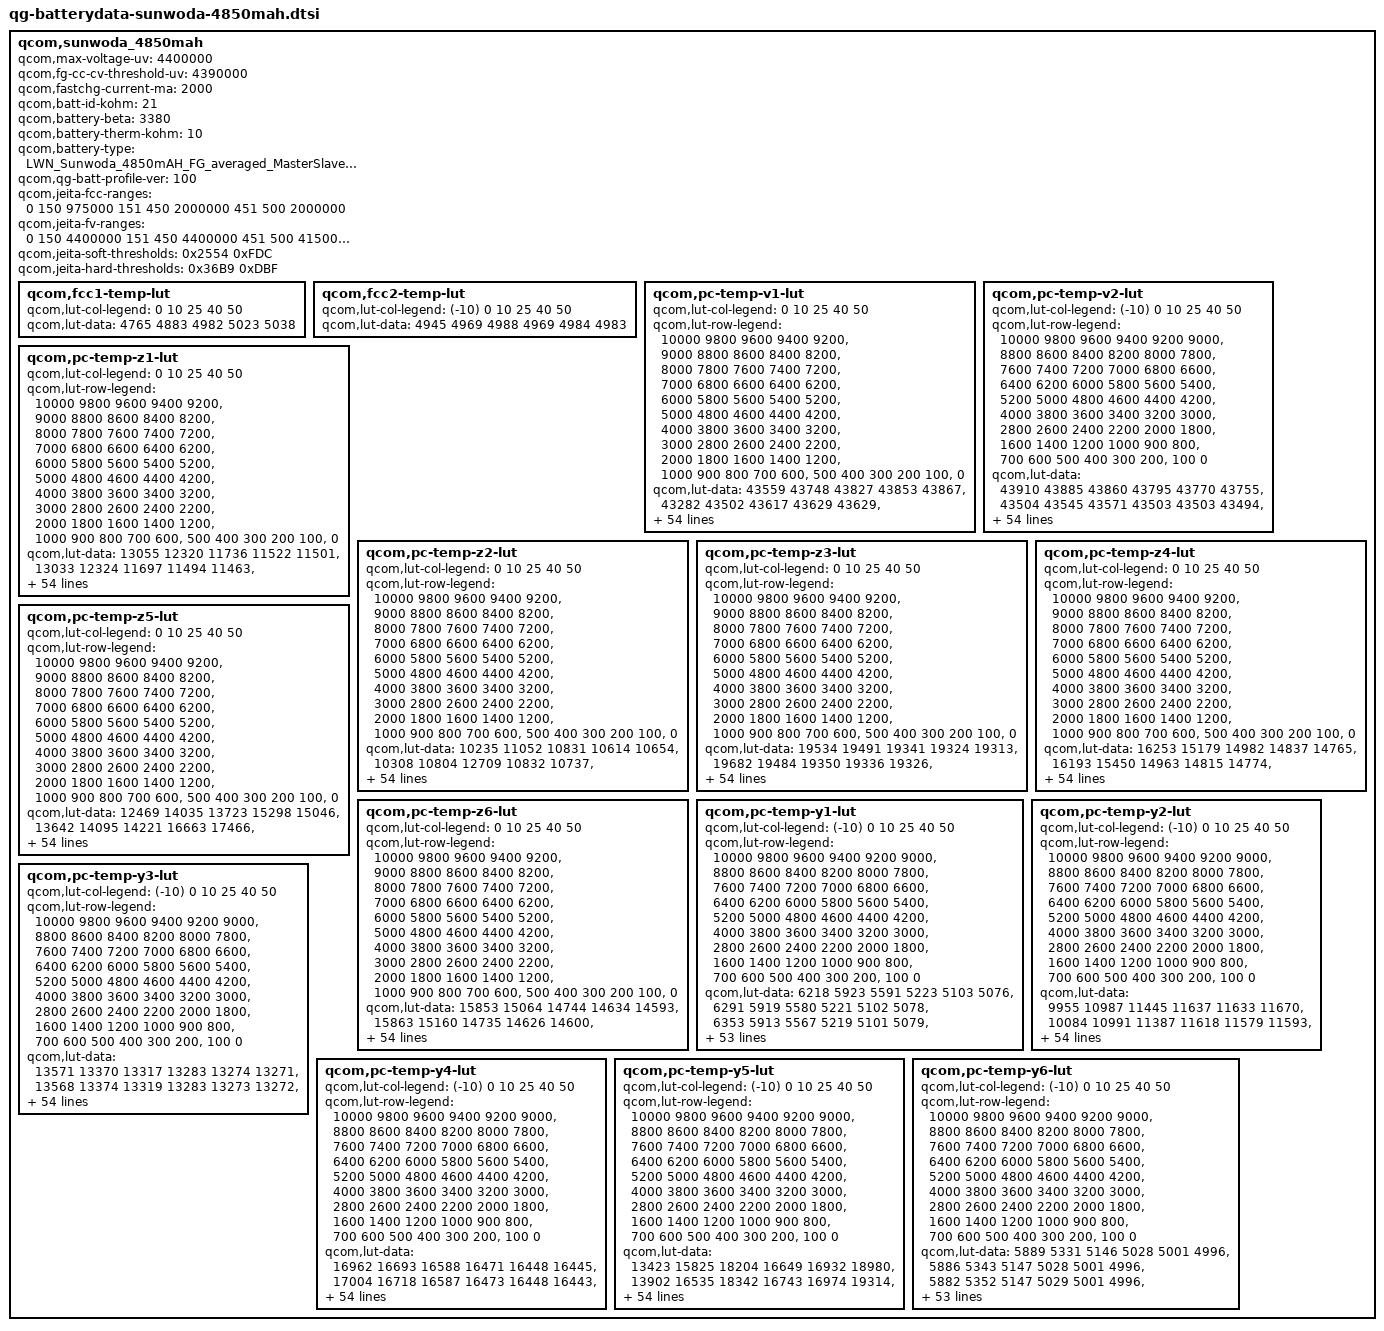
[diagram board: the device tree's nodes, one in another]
/* Copyright (c) 2018, The Linux Foundation. All rights reserved.
 *
 * This program is free software; you can redistribute it and/or modify
 * it under the terms of the GNU General Public License version 2 and
 * only version 2 as published by the Free Software Foundation.
 *
 * This program is distributed in the hope that it will be useful,
 * but WITHOUT ANY WARRANTY; without even the implied warranty of
 * MERCHANTABILITY or FITNESS FOR A PARTICULAR PURPOSE.  See the
 * GNU General Public License for more details.
 */

qcom,sunwoda_4850mah {
    /* 3757018_LC_P400_Sunwoda_4850mAH_FG_averaged_MasterSlave_Jan3th2019 */
    qcom,max-voltage-uv = <4400000>;
    qcom,fg-cc-cv-threshold-uv = <4390000>;
    qcom,fastchg-current-ma = <2000>;
    qcom,batt-id-kohm = <21>;
    qcom,battery-beta = <3380>;
    qcom,battery-therm-kohm = <10>;
    qcom,battery-type = "LWN_Sunwoda_4850mAH_FG_averaged_MasterSlave_Jan3th2019";
    qcom,qg-batt-profile-ver = <100>;

	qcom,jeita-fcc-ranges = <0   150   975000
				151  450  2000000
				451  500  2000000>;
	qcom,jeita-fv-ranges =  <0   150  4400000
				151  450  4400000
				451  500  4150000>;

	/* COOL = 15 DegC, WARM = 45 DegC */
	qcom,jeita-soft-thresholds = <0x2554 0xFDC>;
	/* COLD = 0 DegC, HOT = 50 DegC */
	qcom,jeita-hard-thresholds = <0x36B9 0xDBF>;

	qcom,fcc1-temp-lut {
		qcom,lut-col-legend = <0 10 25 40 50>;
		qcom,lut-data = <4765 4883 4982 5023 5038>;
	};

	qcom,fcc2-temp-lut {
		qcom,lut-col-legend = <(-10) 0 10 25 40 50>;
		qcom,lut-data = <4945 4969 4988 4969 4984 4983>;
	};

	qcom,pc-temp-v1-lut {
		qcom,lut-col-legend = <0 10 25 40 50>;
		qcom,lut-row-legend = <10000 9800 9600 9400 9200>,
			<9000 8800 8600 8400 8200>,
			<8000 7800 7600 7400 7200>,
			<7000 6800 6600 6400 6200>,
			<6000 5800 5600 5400 5200>,
			<5000 4800 4600 4400 4200>,
			<4000 3800 3600 3400 3200>,
			<3000 2800 2600 2400 2200>,
			<2000 1800 1600 1400 1200>,
			<1000 900 800 700 600>,
			<500 400 300 200 100>,
			<0>;
		qcom,lut-data = <43559 43748 43827 43853 43867>,
			<43282 43502 43617 43629 43629>,
			<43027 43242 43397 43402 43411>,
			<42793 42990 43144 43171 43183>,
			<42570 42751 42892 42939 42951>,
			<42350 42518 42646 42702 42717>,
			<42137 42289 42404 42463 42482>,
			<41926 42065 42169 42226 42249>,
			<41715 41847 41941 41993 42018>,
			<41512 41631 41718 41763 41790>,
			<41334 41425 41494 41537 41562>,
			<41176 41251 41286 41317 41338>,
			<40983 41098 41112 41106 41119>,
			<40685 40902 40947 40905 40905>,
			<40362 40587 40723 40697 40697>,
			<40122 40267 40407 40468 40495>,
			<39926 40060 40148 40249 40300>,
			<39772 39900 39997 40074 40116>,
			<39665 39763 39874 39921 39941>,
			<39573 39652 39735 39767 39772>,
			<39464 39539 39591 39614 39616>,
			<39339 39391 39414 39442 39449>,
			<39210 39215 39142 39192 39219>,
			<39079 39026 38879 38921 38961>,
			<38947 38803 38729 38760 38789>,
			<38813 38614 38622 38658 38675>,
			<38671 38511 38529 38564 38573>,
			<38547 38439 38449 38466 38466>,
			<38456 38377 38376 38374 38367>,
			<38382 38322 38305 38288 38277>,
			<38330 38275 38240 38209 38196>,
			<38292 38234 38181 38139 38124>,
			<38261 38197 38127 38079 38062>,
			<38235 38165 38078 38024 38004>,
			<38214 38137 38039 37972 37947>,
			<38189 38109 38004 37923 37892>,
			<38166 38080 37967 37875 37832>,
			<38136 38047 37930 37828 37771>,
			<38087 37999 37881 37771 37701>,
			<38010 37914 37800 37689 37618>,
			<37916 37811 37697 37588 37520>,
			<37794 37698 37585 37478 37410>,
			<37652 37566 37456 37352 37280>,
			<37487 37407 37302 37200 37128>,
			<37343 37262 37157 37058 36989>,
			<37242 37162 37064 36969 36907>,
			<37218 37137 37040 36945 36884>,
			<37187 37114 37023 36930 36868>,
			<37160 37093 37007 36913 36851>,
			<37121 37057 36970 36867 36799>,
			<36933 36861 36758 36634 36546>,
			<36506 36443 36340 36209 36116>,
			<35946 35880 35777 35644 35551>,
			<35189 35121 35012 34877 34785>,
			<34007 33947 33837 33700 33602>,
			<30000 30000 30000 30000 30000>;
	};

	qcom,pc-temp-v2-lut {
		qcom,lut-col-legend = <(-10) 0 10 25 40 50>;
		qcom,lut-row-legend = <10000 9800 9600 9400 9200 9000>,
			<8800 8600 8400 8200 8000 7800>,
			<7600 7400 7200 7000 6800 6600>,
			<6400 6200 6000 5800 5600 5400>,
			<5200 5000 4800 4600 4400 4200>,
			<4000 3800 3600 3400 3200 3000>,
			<2800 2600 2400 2200 2000 1800>,
			<1600 1400 1200 1000 900 800>,
			<700 600 500 400 300 200>,
			<100 0>;
		qcom,lut-data = <43910 43885 43860 43795 43770 43755>,
			<43504 43545 43571 43503 43503 43494>,
			<43144 43234 43297 43228 43244 43239>,
			<42835 42957 43037 42971 42996 42994>,
			<42567 42710 42790 42731 42758 42758>,
			<42328 42468 42548 42495 42522 42523>,
			<42125 42222 42309 42260 42288 42288>,
			<41926 41984 42074 42028 42056 42055>,
			<41634 41764 41848 41802 41827 41825>,
			<41255 41556 41628 41581 41601 41598>,
			<41115 41354 41409 41361 41377 41374>,
			<41137 41162 41186 41138 41154 41156>,
			<41161 40970 40976 40923 40938 40941>,
			<40928 40779 40805 40737 40742 40734>,
			<40254 40581 40648 40564 40555 40530>,
			<39807 40313 40426 40355 40356 40333>,
			<39585 39887 40091 40076 40140 40140>,
			<39407 39538 39793 39837 39939 39957>,
			<39240 39395 39609 39707 39776 39790>,
			<39091 39294 39455 39602 39624 39626>,
			<38931 39157 39279 39438 39436 39436>,
			<38761 38980 39085 39183 39209 39216>,
			<38593 38809 38909 38947 38998 39008>,
			<38416 38660 38757 38772 38810 38818>,
			<38250 38521 38619 38621 38643 38647>,
			<38157 38393 38497 38496 38512 38512>,
			<38101 38273 38388 38390 38404 38402>,
			<38054 38164 38287 38293 38305 38301>,
			<38012 38057 38195 38203 38213 38210>,
			<37974 37968 38108 38120 38128 38126>,
			<37934 37918 38023 38046 38053 38048>,
			<37893 37883 37942 37977 37984 37976>,
			<37852 37852 37877 37914 37920 37912>,
			<37809 37823 37824 37854 37862 37857>,
			<37765 37795 37780 37798 37801 37795>,
			<37717 37763 37745 37743 37721 37701>,
			<37665 37728 37713 37690 37631 37589>,
			<37607 37688 37673 37630 37546 37490>,
			<37541 37641 37625 37561 37464 37399>,
			<37470 37580 37565 37487 37383 37314>,
			<37398 37486 37483 37412 37311 37241>,
			<37320 37371 37384 37325 37227 37160>,
			<37238 37255 37269 37209 37113 37045>,
			<37151 37132 37136 37078 36986 36918>,
			<37062 37011 36994 36929 36845 36785>,
			<36966 36916 36922 36880 36807 36749>,
			<36920 36881 36903 36867 36795 36738>,
			<36875 36850 36885 36851 36782 36727>,
			<36827 36801 36859 36829 36757 36701>,
			<36752 36727 36802 36773 36691 36620>,
			<36603 36552 36611 36584 36445 36347>,
			<36274 36179 36180 36142 35984 35875>,
			<35755 35599 35574 35546 35373 35258>,
			<34996 34802 34747 34753 34546 34410>,
			<33825 33539 33456 33568 33298 33144>,
			<31360 29501 29420 29354 29436 29519>;
	};

	qcom,pc-temp-z1-lut {
		qcom,lut-col-legend = <0 10 25 40 50>;
		qcom,lut-row-legend = <10000 9800 9600 9400 9200>,
			<9000 8800 8600 8400 8200>,
			<8000 7800 7600 7400 7200>,
			<7000 6800 6600 6400 6200>,
			<6000 5800 5600 5400 5200>,
			<5000 4800 4600 4400 4200>,
			<4000 3800 3600 3400 3200>,
			<3000 2800 2600 2400 2200>,
			<2000 1800 1600 1400 1200>,
			<1000 900 800 700 600>,
			<500 400 300 200 100>,
			<0>;
		qcom,lut-data = <13055 12320 11736 11522 11501>,
			<13033 12324 11697 11494 11463>,
			<13010 12288 11679 11483 11455>,
			<12993 12262 11665 11476 11450>,
			<12988 12250 11655 11471 11447>,
			<12991 12241 11649 11468 11446>,
			<12995 12227 11644 11465 11445>,
			<12993 12208 11639 11465 11445>,
			<12954 12196 11634 11465 11447>,
			<12911 12191 11633 11466 11448>,
			<12908 12188 11635 11466 11448>,
			<12918 12183 11636 11465 11448>,
			<12922 12179 11637 11466 11448>,
			<12905 12172 11637 11467 11448>,
			<12873 12151 11635 11468 11448>,
			<12839 12133 11623 11465 11449>,
			<12796 12132 11616 11462 11449>,
			<12776 12135 11621 11463 11450>,
			<12777 12138 11628 11466 11451>,
			<12780 12143 11634 11468 11452>,
			<12783 12150 11639 11469 11453>,
			<12794 12162 11644 11470 11454>,
			<12806 12180 11647 11471 11455>,
			<12818 12188 11650 11473 11456>,
			<12832 12192 11654 11475 11457>,
			<12837 12195 11658 11478 11460>,
			<12837 12197 11662 11481 11463>,
			<12839 12199 11666 11483 11465>,
			<12856 12202 11670 11485 11467>,
			<12884 12207 11675 11488 11469>,
			<12892 12212 11680 11492 11471>,
			<12882 12217 11684 11495 11472>,
			<12872 12221 11688 11497 11475>,
			<12872 12224 11692 11498 11477>,
			<12874 12226 11697 11501 11479>,
			<12878 12229 11703 11503 11480>,
			<12889 12233 11708 11505 11482>,
			<12903 12240 11712 11508 11483>,
			<12913 12246 11717 11510 11484>,
			<12923 12252 11720 11512 11485>,
			<12929 12260 11724 11513 11487>,
			<12942 12276 11729 11516 11488>,
			<12950 12292 11734 11518 11490>,
			<12944 12296 11740 11521 11492>,
			<12946 12294 11748 11524 11493>,
			<12949 12305 11754 11526 11494>,
			<12921 12300 11753 11525 11494>,
			<12937 12292 11758 11526 11493>,
			<12919 12290 11757 11526 11494>,
			<12941 12319 11759 11528 11496>,
			<12939 12331 11769 11532 11498>,
			<12934 12340 11778 11537 11503>,
			<12946 12335 11789 11546 11510>,
			<13009 12379 11811 11558 11519>,
			<13009 12379 11811 11558 11519>,
			<13009 12379 11811 11558 11519>;
	};

	qcom,pc-temp-z2-lut {
		qcom,lut-col-legend = <0 10 25 40 50>;
		qcom,lut-row-legend = <10000 9800 9600 9400 9200>,
			<9000 8800 8600 8400 8200>,
			<8000 7800 7600 7400 7200>,
			<7000 6800 6600 6400 6200>,
			<6000 5800 5600 5400 5200>,
			<5000 4800 4600 4400 4200>,
			<4000 3800 3600 3400 3200>,
			<3000 2800 2600 2400 2200>,
			<2000 1800 1600 1400 1200>,
			<1000 900 800 700 600>,
			<500 400 300 200 100>,
			<0>;
		qcom,lut-data = <10235 11052 10831 10614 10654>,
			<10308 10804 12709 10832 10737>,
			<10347 10628 13825 11026 10757>,
			<10370 10537 12805 11506 10788>,
			<10389 10496 11906 11836 10820>,
			<10409 10464 11172 11546 10816>,
			<10429 10443 10705 10950 10774>,
			<10434 10426 10750 10790 10748>,
			<10423 10420 10930 10769 10667>,
			<10405 10418 11025 10761 10602>,
			<10391 10417 11236 11003 10576>,
			<10376 10420 11403 11351 10524>,
			<10358 10429 11373 11425 10521>,
			<10333 10435 11312 11443 10545>,
			<10305 10434 11332 11471 10571>,
			<10286 10434 11516 11546 10596>,
			<10269 10437 11627 11607 10621>,
			<10263 10445 11266 11377 10644>,
			<10274 10460 10774 10835 10665>,
			<10296 10506 10737 10684 10692>,
			<10315 10565 10838 10726 10734>,
			<10332 10617 10901 10768 10764>,
			<10350 10667 10908 10792 10762>,
			<10371 10702 10905 10815 10756>,
			<10394 10728 10896 10818 10772>,
			<10423 10742 10874 10812 10880>,
			<10463 10738 10863 10832 10971>,
			<10491 10725 10881 10913 11008>,
			<10500 10718 10903 10998 11013>,
			<10505 10714 10933 11000 10925>,
			<10505 10712 10979 10952 10722>,
			<10500 10718 10995 10931 10616>,
			<10495 10732 10998 10887 10609>,
			<10491 10746 10998 10850 10630>,
			<10490 10759 10988 10879 10676>,
			<10492 10771 10974 10948 10754>,
			<10504 10780 10982 11023 10841>,
			<10520 10789 11015 11114 10949>,
			<10539 10804 11051 11191 11030>,
			<10564 10833 11090 11253 11072>,
			<10585 10852 11125 11296 11103>,
			<10599 10850 11142 11279 11120>,
			<10619 10847 11152 11204 11114>,
			<10665 10859 11154 11137 11076>,
			<10936 10976 11180 11106 11041>,
			<11079 11096 11217 11118 11031>,
			<10952 11113 11165 11115 11018>,
			<10938 11143 11128 11093 10996>,
			<10920 11174 11179 11120 11062>,
			<10854 11221 11170 11271 11332>,
			<10961 11264 11432 11191 10927>,
			<10790 11386 11359 10961 10717>,
			<10568 11294 11363 10862 10591>,
			<10341 11158 11347 10768 10593>,
			<10341 11158 11347 10768 10593>,
			<10341 11158 11347 10768 10593>;
	};

	qcom,pc-temp-z3-lut {
		qcom,lut-col-legend = <0 10 25 40 50>;
		qcom,lut-row-legend = <10000 9800 9600 9400 9200>,
			<9000 8800 8600 8400 8200>,
			<8000 7800 7600 7400 7200>,
			<7000 6800 6600 6400 6200>,
			<6000 5800 5600 5400 5200>,
			<5000 4800 4600 4400 4200>,
			<4000 3800 3600 3400 3200>,
			<3000 2800 2600 2400 2200>,
			<2000 1800 1600 1400 1200>,
			<1000 900 800 700 600>,
			<500 400 300 200 100>,
			<0>;
		qcom,lut-data = <19534 19491 19341 19324 19313>,
			<19682 19484 19350 19336 19326>,
			<19726 19549 19364 19370 19347>,
			<19728 19578 19422 19383 19357>,
			<19728 19579 19448 19389 19363>,
			<19716 19580 19446 19389 19366>,
			<19685 19580 19444 19386 19368>,
			<19666 19579 19449 19386 19368>,
			<19659 19578 19458 19385 19364>,
			<19654 19571 19461 19385 19359>,
			<19650 19559 19465 19384 19355>,
			<19646 19545 19468 19383 19350>,
			<19645 19528 19460 19382 19347>,
			<19671 19523 19448 19380 19343>,
			<19704 19531 19446 19378 19341>,
			<19706 19539 19449 19376 19337>,
			<19690 19534 19450 19373 19334>,
			<19670 19515 19420 19362 19331>,
			<19641 19502 19379 19343 19329>,
			<19612 19492 19374 19335 19327>,
			<19604 19487 19375 19332 19324>,
			<19606 19487 19377 19331 19321>,
			<19610 19490 19393 19334 19318>,
			<19615 19495 19409 19339 19316>,
			<19620 19504 19406 19338 19314>,
			<19627 19511 19395 19325 19311>,
			<19642 19509 19386 19318 19310>,
			<19652 19504 19379 19327 19330>,
			<19651 19500 19375 19340 19356>,
			<19649 19496 19377 19348 19358>,
			<19645 19492 19383 19360 19354>,
			<19639 19490 19389 19364 19350>,
			<19631 19488 19396 19359 19342>,
			<19625 19486 19400 19353 19334>,
			<19618 19485 19398 19349 19329>,
			<19611 19483 19394 19345 19325>,
			<19602 19480 19390 19342 19324>,
			<19592 19476 19387 19338 19325>,
			<19584 19472 19383 19335 19325>,
			<19577 19468 19379 19334 19324>,
			<19569 19464 19376 19333 19323>,
			<19559 19461 19375 19332 19324>,
			<19548 19457 19375 19331 19327>,
			<19536 19451 19372 19330 19327>,
			<19478 19429 19365 19326 19325>,
			<19434 19409 19354 19320 19314>,
			<19326 19399 19350 19317 19311>,
			<19319 19390 19343 19314 19308>,
			<19307 19386 19340 19313 19302>,
			<19295 19386 19331 19306 19294>,
			<19308 19381 19319 19313 19320>,
			<19319 19346 19320 19321 19324>,
			<19322 19353 19317 19320 19324>,
			<19317 19329 19310 19320 19312>,
			<19317 19329 19310 19320 19312>,
			<19317 19329 19310 19320 19312>;
	};

	qcom,pc-temp-z4-lut {
		qcom,lut-col-legend = <0 10 25 40 50>;
		qcom,lut-row-legend = <10000 9800 9600 9400 9200>,
			<9000 8800 8600 8400 8200>,
			<8000 7800 7600 7400 7200>,
			<7000 6800 6600 6400 6200>,
			<6000 5800 5600 5400 5200>,
			<5000 4800 4600 4400 4200>,
			<4000 3800 3600 3400 3200>,
			<3000 2800 2600 2400 2200>,
			<2000 1800 1600 1400 1200>,
			<1000 900 800 700 600>,
			<500 400 300 200 100>,
			<0>;
		qcom,lut-data = <16253 15179 14982 14837 14765>,
			<16193 15450 14963 14815 14774>,
			<16088 15343 14997 14864 14817>,
			<15885 15234 14916 14828 14803>,
			<15676 15139 14860 14788 14779>,
			<15548 15052 14838 14771 14760>,
			<15448 14985 14819 14758 14743>,
			<15365 14931 14788 14744 14728>,
			<15297 14892 14748 14726 14714>,
			<15236 14867 14719 14708 14702>,
			<15170 14846 14691 14692 14697>,
			<15102 14819 14669 14677 14693>,
			<15053 14790 14657 14668 14688>,
			<15026 14779 14649 14660 14682>,
			<15003 14779 14648 14656 14676>,
			<14973 14779 14654 14655 14671>,
			<14936 14772 14662 14655 14666>,
			<14901 14752 14674 14656 14660>,
			<14873 14733 14685 14659 14653>,
			<14848 14713 14685 14659 14650>,
			<14830 14699 14680 14659 14650>,
			<14812 14703 14679 14659 14651>,
			<14802 14718 14732 14704 14690>,
			<14799 14740 14790 14780 14768>,
			<14798 14788 14798 14794 14785>,
			<14799 14825 14800 14792 14778>,
			<14809 14823 14800 14790 14768>,
			<14819 14815 14793 14770 14736>,
			<14823 14806 14781 14740 14695>,
			<14827 14797 14766 14717 14680>,
			<14828 14786 14748 14693 14672>,
			<14821 14776 14732 14679 14667>,
			<14812 14766 14716 14672 14662>,
			<14803 14756 14705 14668 14659>,
			<14793 14746 14700 14668 14660>,
			<14782 14737 14697 14669 14661>,
			<14771 14729 14696 14671 14663>,
			<14761 14722 14695 14674 14668>,
			<14750 14720 14695 14678 14673>,
			<14740 14720 14701 14686 14678>,
			<14733 14720 14708 14693 14683>,
			<14730 14714 14705 14691 14680>,
			<14725 14702 14694 14685 14672>,
			<14713 14695 14690 14686 14674>,
			<14699 14678 14680 14685 14675>,
			<14707 14661 14659 14664 14660>,
			<14821 14662 14653 14658 14655>,
			<14825 14661 14648 14646 14642>,
			<14831 14658 14639 14628 14629>,
			<14835 14651 14643 14631 14631>,
			<14819 14664 14674 14650 14633>,
			<14828 14713 14681 14648 14635>,
			<14835 14712 14686 14649 14636>,
			<14853 14746 14696 14650 14647>,
			<14853 14746 14696 14650 14647>,
			<14853 14746 14696 14650 14647>;
	};

	qcom,pc-temp-z5-lut {
		qcom,lut-col-legend = <0 10 25 40 50>;
		qcom,lut-row-legend = <10000 9800 9600 9400 9200>,
			<9000 8800 8600 8400 8200>,
			<8000 7800 7600 7400 7200>,
			<7000 6800 6600 6400 6200>,
			<6000 5800 5600 5400 5200>,
			<5000 4800 4600 4400 4200>,
			<4000 3800 3600 3400 3200>,
			<3000 2800 2600 2400 2200>,
			<2000 1800 1600 1400 1200>,
			<1000 900 800 700 600>,
			<500 400 300 200 100>,
			<0>;
		qcom,lut-data = <12469 14035 13723 15298 15046>,
			<13642 14095 14221 16663 17466>,
			<14305 15310 14148 18876 18921>,
			<14672 16224 16323 19775 19970>,
			<14920 16679 17824 20300 20922>,
			<15069 17072 18500 20653 21636>,
			<15176 17710 19092 20971 22319>,
			<15319 18576 20359 21446 22605>,
			<15574 19117 22701 22366 22672>,
			<15898 19386 25071 23412 22729>,
			<16197 19556 28943 25500 22668>,
			<16499 19620 32210 28306 22437>,
			<17011 19699 33609 30520 22407>,
			<18890 19942 34526 32847 22821>,
			<20877 21937 34644 33999 23114>,
			<21144 23939 34341 34303 23274>,
			<21040 23953 33753 34023 23632>,
			<20924 23612 28463 31073 24484>,
			<20812 23648 21720 25630 26114>,
			<20707 26738 21273 24164 27053>,
			<21016 31251 23431 24733 27555>,
			<23097 34895 27080 25429 27842>,
			<25786 38531 39736 27253 26755>,
			<28359 42484 51620 29884 24083>,
			<31418 47804 48029 28926 21521>,
			<35614 51380 35896 21903 17985>,
			<42899 49221 28515 17730 16140>,
			<48146 43367 24502 17839 18570>,
			<48673 39546 22487 18708 22498>,
			<47979 37102 22699 20617 24742>,
			<46797 35799 23455 24327 26440>,
			<44614 35875 24886 27151 27187>,
			<42340 36219 29082 28917 27269>,
			<40820 36758 32941 30592 27358>,
			<39559 37974 35318 33008 28319>,
			<38523 39284 36967 35395 30180>,
			<37497 40320 37188 35668 31447>,
			<36835 41234 36986 34363 32419>,
			<37223 41644 36562 32568 32850>,
			<38515 41861 34189 29751 29712>,
			<39046 41892 31740 26807 25242>,
			<37145 41026 31719 25695 25094>,
			<35868 39551 32058 25095 26328>,
			<36417 38635 31164 23775 25718>,
			<31640 36815 30994 23139 24186>,
			<24416 34431 31333 23781 22267>,
			<13476 28486 28947 23008 21353>,
			<13195 25281 26834 23277 22231>,
			<12831 24214 26067 27506 23734>,
			<12521 25299 23048 24590 20660>,
			<13074 23780 17854 19778 24456>,
			<13189 16532 16608 19688 22939>,
			<13016 16266 15599 18353 21661>,
			<12656 14072 14417 17650 16644>,
			<12656 14072 14417 17650 16644>,
			<12656 14072 14417 17650 16644>;
	};

	qcom,pc-temp-z6-lut {
		qcom,lut-col-legend = <0 10 25 40 50>;
		qcom,lut-row-legend = <10000 9800 9600 9400 9200>,
			<9000 8800 8600 8400 8200>,
			<8000 7800 7600 7400 7200>,
			<7000 6800 6600 6400 6200>,
			<6000 5800 5600 5400 5200>,
			<5000 4800 4600 4400 4200>,
			<4000 3800 3600 3400 3200>,
			<3000 2800 2600 2400 2200>,
			<2000 1800 1600 1400 1200>,
			<1000 900 800 700 600>,
			<500 400 300 200 100>,
			<0>;
		qcom,lut-data = <15853 15064 14744 14634 14593>,
			<15863 15160 14735 14626 14600>,
			<15851 15137 14754 14662 14627>,
			<15756 15106 14747 14653 14624>,
			<15638 15063 14738 14641 14619>,
			<15561 15017 14726 14634 14614>,
			<15497 14983 14713 14626 14608>,
			<15446 14957 14701 14619 14601>,
			<15406 14935 14688 14611 14593>,
			<15372 14917 14678 14604 14586>,
			<15336 14902 14669 14596 14581>,
			<15299 14881 14661 14590 14576>,
			<15275 14858 14651 14585 14572>,
			<15266 14848 14641 14581 14567>,
			<15258 14847 14640 14577 14563>,
			<15240 14846 14643 14575 14559>,
			<15207 14840 14644 14573 14555>,
			<15175 14823 14632 14567 14551>,
			<15147 14808 14616 14558 14546>,
			<15125 14796 14613 14554 14544>,
			<15121 14789 14613 14552 14542>,
			<15120 14792 14614 14551 14541>,
			<15119 14803 14646 14573 14557>,
			<15121 14817 14680 14608 14588>,
			<15127 14843 14681 14614 14595>,
			<15134 14863 14678 14608 14592>,
			<15150 14862 14674 14602 14588>,
			<15162 14858 14668 14598 14585>,
			<15165 14853 14662 14594 14581>,
			<15167 14848 14657 14590 14577>,
			<15166 14843 14654 14586 14573>,
			<15163 14838 14651 14582 14568>,
			<15158 14834 14648 14577 14562>,
			<15153 14830 14646 14573 14557>,
			<15149 14826 14643 14570 14554>,
			<15143 14822 14640 14568 14552>,
			<15137 14818 14638 14567 14552>,
			<15131 14815 14636 14567 14553>,
			<15127 14815 14636 14567 14555>,
			<15122 14815 14637 14569 14557>,
			<15118 14815 14639 14572 14558>,
			<15114 14812 14637 14571 14558>,
			<15109 14808 14634 14568 14556>,
			<15101 14804 14631 14568 14558>,
			<15072 14789 14625 14566 14557>,
			<15054 14776 14611 14554 14545>,
			<15048 14771 14607 14550 14541>,
			<15049 14767 14602 14543 14534>,
			<15045 14764 14596 14535 14525>,
			<15044 14764 14594 14533 14521>,
			<15052 14772 14603 14545 14537>,
			<15068 14779 14609 14550 14542>,
			<15083 14788 14613 14552 14545>,
			<15106 14803 14618 14556 14546>,
			<15106 14803 14618 14556 14546>,
			<15106 14803 14618 14556 14546>;
	};

	qcom,pc-temp-y1-lut {
		qcom,lut-col-legend = <(-10) 0 10 25 40 50>;
		qcom,lut-row-legend = <10000 9800 9600 9400 9200 9000>,
			<8800 8600 8400 8200 8000 7800>,
			<7600 7400 7200 7000 6800 6600>,
			<6400 6200 6000 5800 5600 5400>,
			<5200 5000 4800 4600 4400 4200>,
			<4000 3800 3600 3400 3200 3000>,
			<2800 2600 2400 2200 2000 1800>,
			<1600 1400 1200 1000 900 800>,
			<700 600 500 400 300 200>,
			<100 0>;
		qcom,lut-data = <6218 5923 5591 5223 5103 5076>,
			<6291 5919 5580 5221 5102 5078>,
			<6353 5913 5567 5219 5101 5079>,
			<6401 5908 5556 5217 5100 5080>,
			<6431 5904 5547 5215 5099 5081>,
			<6440 5904 5541 5213 5098 5081>,
			<6423 5908 5539 5210 5097 5080>,
			<6398 5914 5539 5208 5097 5079>,
			<6382 5914 5537 5207 5096 5079>,
			<6359 5913 5533 5207 5097 5079>,
			<6350 5913 5531 5206 5097 5079>,
			<6365 5915 5529 5205 5096 5080>,
			<6384 5917 5526 5203 5096 5080>,
			<6398 5915 5523 5202 5095 5080>,
			<6415 5911 5518 5201 5095 5080>,
			<6420 5908 5516 5201 5095 5080>,
			<6402 5903 5514 5205 5097 5081>,
			<6387 5899 5513 5209 5098 5082>,
			<6396 5905 5517 5209 5099 5082>,
			<6415 5918 5523 5210 5099 5082>,
			<6422 5927 5525 5210 5099 5083>,
			<6409 5936 5525 5213 5100 5083>,
			<6398 5940 5526 5215 5100 5084>,
			<6385 5928 5531 5218 5101 5085>,
			<6366 5911 5538 5220 5103 5085>,
			<6361 5911 5540 5222 5104 5086>,
			<6381 5925 5541 5224 5105 5088>,
			<6395 5932 5542 5227 5107 5089>,
			<6379 5930 5543 5230 5109 5090>,
			<6358 5929 5543 5233 5111 5091>,
			<6368 5932 5546 5238 5113 5093>,
			<6409 5936 5552 5243 5116 5094>,
			<6428 5940 5554 5249 5118 5096>,
			<6398 5939 5555 5253 5120 5098>,
			<6360 5937 5556 5258 5122 5101>,
			<6351 5933 5558 5260 5124 5102>,
			<6345 5928 5561 5262 5125 5103>,
			<6345 5932 5564 5265 5127 5104>,
			<6363 5947 5570 5268 5128 5106>,
			<6380 5956 5575 5272 5130 5107>,
			<6374 5944 5589 5278 5132 5106>,
			<6357 5932 5600 5283 5134 5106>,
			<6371 5954 5601 5289 5135 5110>,
			<6375 5957 5604 5292 5136 5111>,
			<6397 5951 5615 5294 5138 5112>,
			<6368 5957 5619 5300 5141 5114>,
			<6355 5950 5628 5303 5142 5114>,
			<6397 5971 5631 5304 5143 5114>,
			<6407 5954 5629 5309 5143 5114>,
			<6402 5953 5638 5310 5143 5115>,
			<6382 5964 5628 5314 5144 5116>,
			<6375 5968 5643 5323 5149 5119>,
			<6438 5967 5652 5338 5155 5124>,
			<6525 6003 5692 5355 5163 5130>,
			<6525 6003 5692 5355 5163 5130>,
			<6525 6003 5692 5355 5163 5130>;
	};

	qcom,pc-temp-y2-lut {
		qcom,lut-col-legend = <(-10) 0 10 25 40 50>;
		qcom,lut-row-legend = <10000 9800 9600 9400 9200 9000>,
			<8800 8600 8400 8200 8000 7800>,
			<7600 7400 7200 7000 6800 6600>,
			<6400 6200 6000 5800 5600 5400>,
			<5200 5000 4800 4600 4400 4200>,
			<4000 3800 3600 3400 3200 3000>,
			<2800 2600 2400 2200 2000 1800>,
			<1600 1400 1200 1000 900 800>,
			<700 600 500 400 300 200>,
			<100 0>;
		qcom,lut-data = <9955 10987 11445 11637 11633 11670>,
			<10084 10991 11387 11618 11579 11593>,
			<10202 10990 11331 11580 11508 11516>,
			<10299 10984 11278 11535 11434 11442>,
			<10364 10975 11231 11494 11375 11375>,
			<10384 10964 11190 11468 11345 11317>,
			<10351 10950 11150 11449 11335 11258>,
			<10310 10931 11120 11427 11327 11213>,
			<10514 10885 11111 11388 11306 11199>,
			<11214 10803 11107 11327 11270 11188>,
			<11504 10778 11102 11295 11254 11185>,
			<11034 10897 11096 11285 11257 11184>,
			<10538 11065 11093 11277 11264 11181>,
			<10579 11213 11122 11262 11268 11170>,
			<10797 11355 11200 11244 11273 11156>,
			<10963 11380 11276 11252 11285 11156>,
			<11077 11286 11370 11381 11335 11190>,
			<11161 11214 11433 11528 11403 11235>,
			<11219 11260 11454 11635 11536 11327>,
			<11262 11343 11470 11722 11688 11464>,
			<11265 11364 11480 11728 11714 11569>,
			<11192 11362 11494 11678 11709 11669>,
			<11061 11363 11511 11647 11700 11709>,
			<10573 11389 11540 11676 11666 11656>,
			<9883 11422 11571 11728 11631 11593>,
			<9723 11418 11590 11771 11652 11599>,
			<9705 11386 11604 11815 11736 11644>,
			<9696 11374 11622 11843 11796 11691>,
			<9689 11444 11651 11868 11826 11736>,
			<9684 11521 11672 11891 11858 11788>,
			<9680 11514 11666 11899 11930 11854>,
			<9676 11476 11652 11905 12046 11937>,
			<9673 11437 11645 11906 12140 12053>,
			<9669 11399 11645 11897 12228 12254>,
			<9666 11355 11643 11886 12273 12379>,
			<9664 11305 11624 11878 12148 12250>,
			<9663 11246 11588 11867 11926 12003>,
			<9662 11174 11544 11848 11848 11869>,
			<9661 11090 11485 11794 11825 11783>,
			<9660 10951 11424 11747 11819 11739>,
			<9660 10283 11372 11730 11811 11768>,
			<9660 9692 11309 11714 11797 11772>,
			<9659 9682 11214 11669 11769 11613>,
			<9659 9675 11143 11629 11818 11731>,
			<9659 9679 11142 11608 11754 11707>,
			<9658 9671 11031 11473 11532 11458>,
			<9658 9667 10977 11465 11510 11380>,
			<9658 9665 10934 11473 11521 11337>,
			<9658 9663 10880 11439 11536 11331>,
			<9657 9661 10845 11424 11555 11295>,
			<9657 9660 10782 11380 11495 11283>,
			<9657 9658 10667 11314 11301 11192>,
			<9655 9657 10534 11201 11239 11075>,
			<9653 9655 10392 11089 11144 10941>,
			<9653 9655 10392 11089 11144 10941>,
			<9653 9655 10392 11089 11144 10941>;
	};

	qcom,pc-temp-y3-lut {
		qcom,lut-col-legend = <(-10) 0 10 25 40 50>;
		qcom,lut-row-legend = <10000 9800 9600 9400 9200 9000>,
			<8800 8600 8400 8200 8000 7800>,
			<7600 7400 7200 7000 6800 6600>,
			<6400 6200 6000 5800 5600 5400>,
			<5200 5000 4800 4600 4400 4200>,
			<4000 3800 3600 3400 3200 3000>,
			<2800 2600 2400 2200 2000 1800>,
			<1600 1400 1200 1000 900 800>,
			<700 600 500 400 300 200>,
			<100 0>;
		qcom,lut-data = <13571 13370 13317 13283 13274 13271>,
			<13568 13374 13319 13283 13273 13272>,
			<13567 13378 13322 13284 13273 13272>,
			<13567 13382 13325 13284 13274 13273>,
			<13568 13385 13327 13285 13275 13273>,
			<13570 13388 13328 13286 13276 13274>,
			<13579 13391 13329 13286 13277 13274>,
			<13589 13393 13330 13287 13279 13275>,
			<13562 13393 13331 13289 13280 13275>,
			<13464 13393 13333 13293 13282 13275>,
			<13412 13394 13334 13295 13283 13276>,
			<13401 13405 13333 13295 13283 13279>,
			<13395 13415 13332 13295 13283 13281>,
			<13405 13405 13335 13297 13285 13281>,
			<13433 13379 13341 13301 13287 13281>,
			<13441 13365 13342 13302 13287 13281>,
			<13425 13357 13333 13298 13286 13280>,
			<13407 13354 13326 13295 13285 13280>,
			<13397 13353 13324 13297 13286 13281>,
			<13389 13353 13323 13300 13287 13283>,
			<13383 13352 13320 13299 13287 13283>,
			<13379 13348 13316 13295 13284 13281>,
			<13374 13343 13312 13290 13281 13278>,
			<13366 13340 13310 13286 13278 13275>,
			<13356 13337 13309 13283 13276 13273>,
			<13346 13334 13308 13283 13275 13272>,
			<13333 13331 13308 13283 13275 13271>,
			<13327 13327 13307 13283 13275 13271>,
			<13335 13320 13307 13283 13274 13272>,
			<13353 13314 13306 13284 13273 13273>,
			<13371 13314 13305 13284 13274 13272>,
			<13394 13317 13304 13285 13274 13272>,
			<13422 13321 13303 13285 13275 13272>,
			<13459 13325 13304 13285 13275 13273>,
			<13504 13329 13304 13285 13276 13274>,
			<13553 13332 13305 13285 13275 13273>,
			<13607 13336 13307 13286 13274 13271>,
			<13662 13339 13309 13286 13274 13271>,
			<13716 13343 13312 13285 13274 13271>,
			<13768 13348 13314 13285 13274 13271>,
			<13818 13355 13315 13286 13274 13273>,
			<13866 13366 13316 13287 13275 13274>,
			<13910 13391 13316 13287 13275 13274>,
			<13950 13419 13317 13287 13275 13273>,
			<13896 13403 13313 13282 13272 13270>,
			<13968 13455 13316 13288 13277 13274>,
			<14029 13493 13319 13291 13279 13276>,
			<14089 13543 13324 13293 13282 13280>,
			<14146 13609 13331 13298 13284 13282>,
			<14214 13687 13338 13300 13286 13281>,
			<14290 13769 13344 13301 13282 13279>,
			<14382 13846 13346 13299 13282 13279>,
			<14666 13981 13357 13304 13284 13281>,
			<15062 14229 13379 13312 13289 13284>,
			<15062 14229 13379 13312 13289 13284>,
			<15062 14229 13379 13312 13289 13284>;
	};

	qcom,pc-temp-y4-lut {
		qcom,lut-col-legend = <(-10) 0 10 25 40 50>;
		qcom,lut-row-legend = <10000 9800 9600 9400 9200 9000>,
			<8800 8600 8400 8200 8000 7800>,
			<7600 7400 7200 7000 6800 6600>,
			<6400 6200 6000 5800 5600 5400>,
			<5200 5000 4800 4600 4400 4200>,
			<4000 3800 3600 3400 3200 3000>,
			<2800 2600 2400 2200 2000 1800>,
			<1600 1400 1200 1000 900 800>,
			<700 600 500 400 300 200>,
			<100 0>;
		qcom,lut-data = <16962 16693 16588 16471 16448 16445>,
			<17004 16718 16587 16473 16448 16443>,
			<17048 16751 16586 16474 16448 16441>,
			<17089 16785 16586 16476 16448 16441>,
			<17123 16811 16586 16478 16448 16440>,
			<17147 16819 16586 16480 16448 16440>,
			<17158 16815 16586 16482 16449 16441>,
			<17169 16809 16586 16486 16450 16443>,
			<17204 16812 16589 16488 16450 16445>,
			<17291 16824 16598 16489 16452 16448>,
			<17414 16841 16606 16491 16455 16450>,
			<17681 16867 16612 16498 16459 16451>,
			<17907 16903 16619 16509 16465 16452>,
			<17708 16971 16662 16521 16473 16456>,
			<17139 17060 16736 16537 16484 16462>,
			<16900 17058 16748 16550 16493 16469>,
			<16861 16831 16707 16559 16500 16477>,
			<16842 16654 16668 16571 16509 16485>,
			<16837 16680 16652 16598 16527 16499>,
			<16834 16727 16639 16629 16545 16512>,
			<16822 16731 16615 16623 16544 16512>,
			<16765 16693 16575 16556 16524 16504>,
			<16712 16656 16548 16503 16500 16491>,
			<16690 16634 16534 16483 16473 16468>,
			<16675 16615 16526 16471 16451 16447>,
			<16675 16595 16522 16470 16449 16445>,
			<16690 16577 16521 16472 16451 16447>,
			<16699 16559 16520 16473 16454 16449>,
			<16699 16540 16520 16478 16461 16454>,
			<16699 16527 16520 16483 16469 16460>,
			<16701 16527 16516 16489 16477 16467>,
			<16709 16531 16507 16496 16486 16477>,
			<16716 16537 16501 16500 16494 16485>,
			<16722 16547 16497 16503 16503 16496>,
			<16726 16561 16495 16504 16508 16501>,
			<16732 16580 16501 16502 16497 16491>,
			<16738 16603 16513 16495 16477 16470>,
			<16742 16624 16524 16488 16465 16459>,
			<16744 16642 16535 16478 16457 16452>,
			<16745 16662 16545 16473 16453 16449>,
			<16744 16692 16551 16477 16460 16455>,
			<16741 16711 16558 16482 16465 16459>,
			<16740 16697 16567 16486 16463 16456>,
			<16741 16685 16566 16486 16461 16454>,
			<16720 16659 16531 16469 16443 16437>,
			<16726 16669 16548 16476 16450 16445>,
			<16737 16688 16566 16486 16459 16455>,
			<16756 16717 16587 16499 16472 16470>,
			<16785 16740 16615 16520 16493 16494>,
			<16814 16782 16651 16541 16505 16499>,
			<16820 16801 16654 16536 16474 16462>,
			<16802 16804 16633 16511 16459 16448>,
			<16862 16809 16647 16519 16462 16450>,
			<17025 16881 16678 16546 16477 16461>,
			<17025 16881 16678 16546 16477 16461>,
			<17025 16881 16678 16546 16477 16461>;
	};

	qcom,pc-temp-y5-lut {
		qcom,lut-col-legend = <(-10) 0 10 25 40 50>;
		qcom,lut-row-legend = <10000 9800 9600 9400 9200 9000>,
			<8800 8600 8400 8200 8000 7800>,
			<7600 7400 7200 7000 6800 6600>,
			<6400 6200 6000 5800 5600 5400>,
			<5200 5000 4800 4600 4400 4200>,
			<4000 3800 3600 3400 3200 3000>,
			<2800 2600 2400 2200 2000 1800>,
			<1600 1400 1200 1000 900 800>,
			<700 600 500 400 300 200>,
			<100 0>;
		qcom,lut-data = <13423 15825 18204 16649 16932 18980>,
			<13902 16535 18342 16743 16974 19314>,
			<14526 17074 18425 16573 16991 19409>,
			<15274 17447 18466 16264 16988 19327>,
			<16127 17661 18480 15944 16968 19128>,
			<17070 17716 18474 15736 16947 18869>,
			<18440 17507 18112 15428 17449 18452>,
			<19577 17257 17604 15134 18042 17951>,
			<18359 17473 17283 15353 18238 17462>,
			<13895 18197 16880 16104 18610 16963>,
			<11996 18382 16498 16367 18489 16883>,
			<13907 16654 15923 15736 17721 17927>,
			<17031 14992 15519 15109 16994 18880>,
			<20659 16317 15543 15062 16734 18495>,
			<24913 19489 15666 15075 16569 17436>,
			<25969 20386 16454 15081 16242 16527>,
			<22947 20090 20681 15090 15529 15623>,
			<20247 19866 23548 15143 15092 15155>,
			<20690 20519 23045 16247 15227 15281>,
			<21977 21802 22271 18516 15587 15626>,
			<22976 22451 22209 20394 16852 16728>,
			<23852 22783 22489 22273 20779 19985>,
			<24306 23066 22672 23133 22805 21664>,
			<20769 23353 22612 21510 22262 21188>,
			<14588 23619 22536 19234 21340 20496>,
			<12947 23902 22715 18992 20560 19723>,
			<12633 24211 23205 19597 19769 18147>,
			<12526 24223 23691 19885 18981 17496>,
			<12679 20884 24207 19886 18017 17494>,
			<12934 17201 24596 20074 17385 17528>,
			<13066 17079 24738 20645 17510 17337>,
			<13140 17575 24824 21566 17973 16892>,
			<13251 18135 24844 22538 18621 16923>,
			<13529 18899 24886 23708 19820 18323>,
			<13853 19506 24849 24634 20916 19592>,
			<14079 19704 24650 25074 21664 19944>,
			<14286 19822 24348 25369 22242 20165>,
			<14351 19904 23978 25121 22192 20349>,
			<14318 20064 23452 23517 21493 20594>,
			<14286 20107 22680 22070 20812 20715>,
			<14311 17407 21040 21488 19953 20711>,
			<14359 14668 19430 20915 19243 20541>,
			<14277 14628 18280 19060 18928 19558>,
			<14073 14443 17947 18742 19236 20219>,
			<13912 14199 18599 17889 18943 19169>,
			<13924 14340 17498 19055 18828 17325>,
			<13949 14284 17188 18587 18049 17344>,
			<14044 14232 17025 18060 18202 18288>,
			<14213 14375 16963 17611 17679 17678>,
			<14346 14706 17111 17391 17892 16830>,
			<14944 15334 17841 17998 18420 18828>,
			<14466 15010 17629 19247 19416 19336>,
			<13381 14141 17565 19449 19540 21203>,
			<11957 13432 17743 20546 23838 24263>,
			<11957 13432 17743 20546 23838 24263>,
			<11957 13432 17743 20546 23838 24263>;
	};

	qcom,pc-temp-y6-lut {
		qcom,lut-col-legend = <(-10) 0 10 25 40 50>;
		qcom,lut-row-legend = <10000 9800 9600 9400 9200 9000>,
			<8800 8600 8400 8200 8000 7800>,
			<7600 7400 7200 7000 6800 6600>,
			<6400 6200 6000 5800 5600 5400>,
			<5200 5000 4800 4600 4400 4200>,
			<4000 3800 3600 3400 3200 3000>,
			<2800 2600 2400 2200 2000 1800>,
			<1600 1400 1200 1000 900 800>,
			<700 600 500 400 300 200>,
			<100 0>;
		qcom,lut-data = <5889 5331 5146 5028 5001 4996>,
			<5886 5343 5147 5028 5001 4996>,
			<5882 5352 5147 5029 5001 4996>,
			<5879 5359 5147 5029 5001 4996>,
			<5876 5363 5146 5030 5002 4997>,
			<5874 5364 5146 5031 5003 4997>,
			<5873 5360 5144 5032 5004 4998>,
			<5872 5356 5143 5033 5005 4999>,
			<5859 5356 5144 5035 5007 5000>,
			<5820 5357 5147 5038 5008 5001>,
			<5806 5359 5149 5040 5010 5002>,
			<5869 5370 5149 5042 5011 5004>,
			<5936 5383 5149 5045 5013 5006>,
			<5892 5393 5162 5050 5016 5008>,
			<5760 5401 5186 5058 5021 5010>,
			<5697 5395 5190 5061 5024 5011>,
			<5679 5328 5172 5062 5025 5013>,
			<5671 5275 5156 5064 5027 5016>,
			<5669 5283 5151 5071 5033 5020>,
			<5668 5297 5146 5082 5039 5025>,
			<5665 5298 5138 5081 5038 5025>,
			<5658 5286 5123 5058 5030 5021>,
			<5649 5275 5113 5040 5020 5015>,
			<5635 5270 5108 5031 5010 5006>,
			<5621 5265 5105 5026 5002 4998>,
			<5621 5261 5105 5026 5002 4997>,
			<5638 5258 5105 5027 5002 4997>,
			<5659 5254 5105 5028 5003 4998>,
			<5680 5250 5107 5029 5005 4999>,
			<5705 5248 5108 5031 5007 5002>,
			<5735 5251 5107 5034 5009 5004>,
			<5771 5262 5105 5037 5012 5006>,
			<5811 5276 5104 5039 5015 5009>,
			<5856 5293 5105 5040 5018 5013>,
			<5904 5314 5106 5041 5020 5015>,
			<5953 5339 5110 5041 5017 5012>,
			<6005 5370 5117 5040 5011 5004>,
			<6054 5405 5125 5038 5007 5001>,
			<6099 5447 5133 5036 5005 5000>,
			<6143 5490 5143 5035 5004 4999>,
			<6182 5529 5152 5037 5007 5002>,
			<6219 5570 5162 5041 5009 5004>,
			<6254 5617 5175 5042 5008 5003>,
			<6288 5666 5185 5043 5008 5002>,
			<6248 5634 5166 5036 5002 4996>,
			<6305 5712 5188 5043 5007 5001>,
			<6354 5763 5205 5049 5011 5006>,
			<6407 5827 5225 5055 5017 5013>,
			<6462 5895 5249 5065 5025 5021>,
			<6527 5979 5276 5074 5030 5022>,
			<6590 6058 5297 5073 5018 5010>,
			<6667 6132 5313 5066 5014 5006>,
			<6953 6255 5366 5076 5017 5009>,
			<7377 6509 5451 5094 5026 5016>,
			<7377 6509 5451 5094 5026 5016>,
			<7377 6509 5451 5094 5026 5016>;
	};

};
